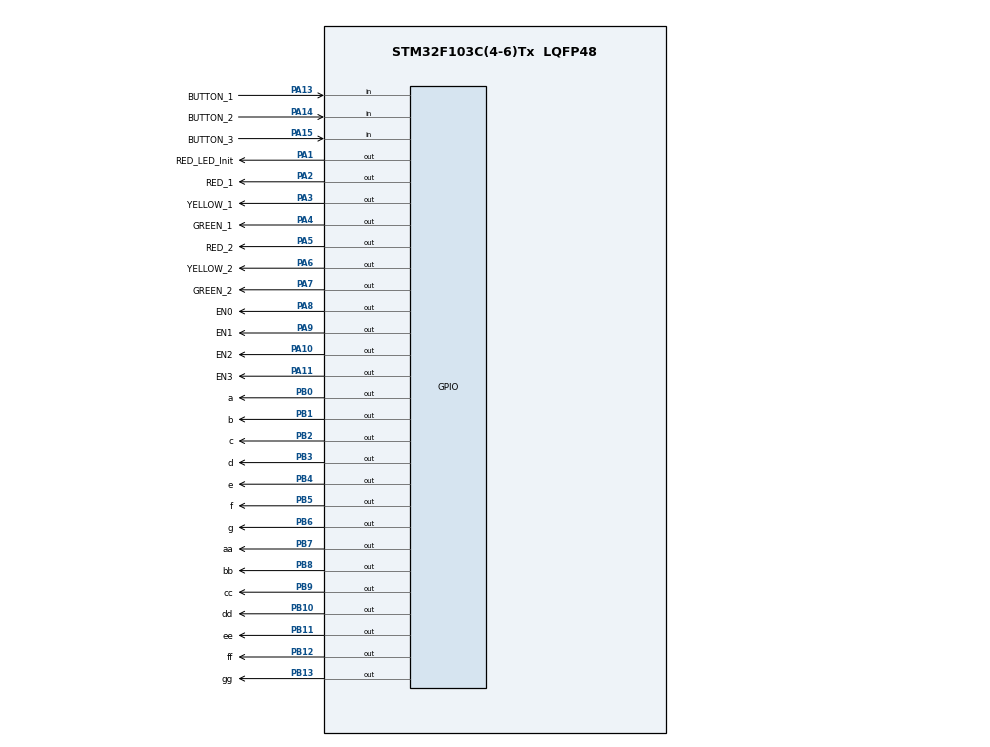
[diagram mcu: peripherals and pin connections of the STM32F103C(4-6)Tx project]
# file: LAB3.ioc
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Mcu.Family=STM32F1
Mcu.Name=STM32F103C(4-6)Tx
Mcu.Package=LQFP48
NVIC.PriorityGroup=NVIC_PRIORITYGROUP_4
NVIC.TIM2_IRQn=true\:1\:0\:true\:false\:true\:true\:true
PA1.GPIO_Label=RED_LED_Init
PA1.GPIO_PuPd=GPIO_PULLUP
PA1.Signal=GPIO_Output
PA10.GPIO_Label=EN2
PA10.Signal=GPIO_Output
PA11.GPIO_Label=EN3
PA11.Signal=GPIO_Output
PA13.GPIO_Label=BUTTON_1
PA13.GPIO_PuPd=GPIO_PULLUP
PA13.Signal=GPIO_Input
PA14.GPIO_Label=BUTTON_2
PA14.GPIO_PuPd=GPIO_PULLUP
PA14.Signal=GPIO_Input
PA15.GPIO_Label=BUTTON_3
PA15.GPIO_PuPd=GPIO_PULLUP
PA15.Signal=GPIO_Input
PA2.GPIO_Label=RED_1
PA2.Signal=GPIO_Output
PA3.GPIO_Label=YELLOW_1
PA3.Signal=GPIO_Output
PA4.GPIO_Label=GREEN_1
PA4.Signal=GPIO_Output
PA5.GPIO_Label=RED_2
PA5.Signal=GPIO_Output
PA6.GPIO_Label=YELLOW_2
PA6.Signal=GPIO_Output
PA7.GPIO_Label=GREEN_2
PA7.Signal=GPIO_Output
PA8.GPIO_Label=EN0
PA8.Signal=GPIO_Output
PA9.GPIO_Label=EN1
PA9.Signal=GPIO_Output
PB0.GPIO_Label=a
PB0.Signal=GPIO_Output
PB1.GPIO_Label=b
PB1.Signal=GPIO_Output
PB10.GPIO_Label=dd
PB10.Signal=GPIO_Output
PB11.GPIO_Label=ee
PB11.Signal=GPIO_Output
PB12.GPIO_Label=ff
PB12.Signal=GPIO_Output
PB13.GPIO_Label=gg
PB13.Signal=GPIO_Output
PB2.GPIO_Label=c
PB2.Signal=GPIO_Output
PB3.GPIO_Label=d
PB3.Signal=GPIO_Output
PB4.GPIO_Label=e
PB4.Signal=GPIO_Output
PB5.GPIO_Label=f
PB5.Signal=GPIO_Output
PB6.GPIO_Label=g
PB6.Signal=GPIO_Output
PB7.GPIO_Label=aa
PB7.Signal=GPIO_Output
PB8.GPIO_Label=bb
PB8.Signal=GPIO_Output
PB9.GPIO_Label=cc
PB9.Signal=GPIO_Output
ProjectManager.HeapSize=0x200
ProjectManager.StackSize=0x400
ProjectManager.TargetToolchain=STM32CubeIDE
RCC.APB1Freq_Value=8000000
RCC.APB2Freq_Value=8000000
TIM2.Period=7999
TIM2.Prescaler=9
VP_SYS_VS_ND.Mode=No_Debug
VP_TIM2_VS_ClockSourceINT.Mode=Internal
board=custom

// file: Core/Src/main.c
/* USER CODE BEGIN Header */
/**
 ******************************************************************************
 * @file           : main.c
 * @brief          : Main program body
 ******************************************************************************
 * @attention
 *
 * <h2><center>&copy; Copyright (c) 2024 STMicroelectronics.
 * All rights reserved.</center></h2>
 *
 * This software component is licensed by ST under BSD 3-Clause license,
 * the "License"; You may not use this file except in compliance with the
 * License. You may obtain a copy of the License at:
 *                        opensource.org/licenses/BSD-3-Clause
 *
 ******************************************************************************
 */
/* USER CODE END Header */
#include "main.h"

/* USER CODE BEGIN Includes */
//#include "fsm_Automatic.h"
#include "software_timer.h"
#include "button.h"
#include "Global.h"
/* USER CODE END Includes */

TIM_HandleTypeDef htim2;

void SystemClock_Config(void);
static void MX_GPIO_Init(void);
static void MX_TIM2_Init(void);

/* USER CODE BEGIN 0 */
//void test_module_MANRED(){
//	if (isButtonPressed(0)) {
//		HAL_GPIO_WritePin(GPIOA, GREEN_1_Pin, LED_ON);
//	}
//	else if (isButtonPressed(2)) {
//		TimeRed = value;
//	}
//	else manual_run(MODE2);
//}
/* USER CODE END 0 */

int main(void)
{

  /* MCU Configuration--------------------------------------------------------*/

  /* Reset of all peripherals, Initializes the Flash interface and the Systick. */
  HAL_Init();

  /* Configure the system clock */
  SystemClock_Config();

  /* Initialize all configured peripherals */
  MX_GPIO_Init();
  MX_TIM2_Init();
  /* USER CODE BEGIN 2 */
	HAL_TIM_Base_Start_IT(&htim2);
//	HAL_GPIO_WritePin(GPIOB,
//			a_Pin |b_Pin | c_Pin | dd_Pin | ee_Pin | ff_Pin | gg_Pin | d_Pin | e_Pin
//					| f_Pin | g_Pin | aa_Pin | bb_Pin | cc_Pin, GPIO_PIN_SET);
//	HAL_GPIO_WritePin(GPIOA,
//			 EN0_Pin | EN1_Pin
//					| EN2_Pin | EN3_Pin, GPIO_PIN_SET);
//	setTimer(5, 1000); //for test module
	//fsm_automatic_init();
//	fsm_manual_init();

	setTimer(1, 239);	//for 4_7SEG
	setTimer(2, 1010);	//for LED_2
//	int TimeForLed1 = 2;
//	setTimer(3, 523); 	//blinking led
//	setTimer(4, 257);	//modified time
	HAL_GPIO_WritePin(GPIOA, ALL_LED, LED_OFF);
	setTimer(0, 1000); 	//for LED_1
  /* USER CODE END 2 */

  /* Infinite loop */
	while (1) {

    /* USER CODE BEGIN 3 */
//		if (HAL_GPIO_ReadPin(GPIOA, BUTTON_1_Pin) == GPIO_PIN_RESET) //pullup: pressed = 0
//			HAL_GPIO_TogglePin(RED_LED_Init_GPIO_Port, RED_LED_Init_Pin);
//		if (isButtonPressed(0) == 1){
//			HAL_GPIO_TogglePin(RED_LED_Init_GPIO_Port, RED_LED_Init_Pin);
//		}
//		if (isButtonPressed(1) == 1){
//			HAL_GPIO_TogglePin(GPIOA, RED_1_Pin);
//		}
//		if (isButtonPressed(2) == 1){
//			HAL_GPIO_TogglePin(GPIOA, RED_2_Pin);
//		}

		fsm_setting_run();
		fsm_automatic_run();
		fsm_manual_run();

//		if (isTimerExpired(5)){
//			HAL_GPIO_TogglePin(GPIOA, RED_1_Pin);
//			setTimer(5, 1000);
//		}
//		test_module_MANRED();

//		if (isTimerExpired(0)) {
////			TimeForLed1--;
////			if (TimeForLed1 <= 0) {
//				HAL_GPIO_TogglePin(GPIOA, RED_1_Pin);
//				setTimer(0, 1000);
////			}
//		}

	}
  /* USER CODE END 3 */
}

void SystemClock_Config(void)
{
  RCC_OscInitTypeDef RCC_OscInitStruct = {0};
  RCC_ClkInitTypeDef RCC_ClkInitStruct = {0};

  /** Initializes the RCC Oscillators according to the specified parameters
  * in the RCC_OscInitTypeDef structure.
  */
  RCC_OscInitStruct.OscillatorType = RCC_OSCILLATORTYPE_HSI;
  RCC_OscInitStruct.HSIState = RCC_HSI_ON;
  RCC_OscInitStruct.HSICalibrationValue = RCC_HSICALIBRATION_DEFAULT;
  RCC_OscInitStruct.PLL.PLLState = RCC_PLL_NONE;
  if (HAL_RCC_OscConfig(&RCC_OscInitStruct) != HAL_OK)
  {
    Error_Handler();
  }
  /** Initializes the CPU, AHB and APB buses clocks
  */
  RCC_ClkInitStruct.ClockType = RCC_CLOCKTYPE_HCLK|RCC_CLOCKTYPE_SYSCLK
                              |RCC_CLOCKTYPE_PCLK1|RCC_CLOCKTYPE_PCLK2;
  RCC_ClkInitStruct.SYSCLKSource = RCC_SYSCLKSOURCE_HSI;
  RCC_ClkInitStruct.AHBCLKDivider = RCC_SYSCLK_DIV1;
  RCC_ClkInitStruct.APB1CLKDivider = RCC_HCLK_DIV1;
  RCC_ClkInitStruct.APB2CLKDivider = RCC_HCLK_DIV1;

  if (HAL_RCC_ClockConfig(&RCC_ClkInitStruct, FLASH_LATENCY_0) != HAL_OK)
  {
    Error_Handler();
  }
}

static void MX_TIM2_Init(void)
{

  TIM_ClockConfigTypeDef sClockSourceConfig = {0};
  TIM_MasterConfigTypeDef sMasterConfig = {0};

  htim2.Instance = TIM2;
  htim2.Init.Prescaler = 9;
  htim2.Init.CounterMode = TIM_COUNTERMODE_UP;
  htim2.Init.Period = 7999;
  htim2.Init.ClockDivision = TIM_CLOCKDIVISION_DIV1;
  htim2.Init.AutoReloadPreload = TIM_AUTORELOAD_PRELOAD_DISABLE;
  if (HAL_TIM_Base_Init(&htim2) != HAL_OK)
  {
    Error_Handler();
  }
  sClockSourceConfig.ClockSource = TIM_CLOCKSOURCE_INTERNAL;
  if (HAL_TIM_ConfigClockSource(&htim2, &sClockSourceConfig) != HAL_OK)
  {
    Error_Handler();
  }
  sMasterConfig.MasterOutputTrigger = TIM_TRGO_RESET;
  sMasterConfig.MasterSlaveMode = TIM_MASTERSLAVEMODE_DISABLE;
  if (HAL_TIMEx_MasterConfigSynchronization(&htim2, &sMasterConfig) != HAL_OK)
  {
    Error_Handler();
  }

}

static void MX_GPIO_Init(void)
{
  GPIO_InitTypeDef GPIO_InitStruct = {0};

  /* GPIO Ports Clock Enable */
  __HAL_RCC_GPIOA_CLK_ENABLE();
  __HAL_RCC_GPIOB_CLK_ENABLE();

  /*Configure GPIO pin Output Level */
  HAL_GPIO_WritePin(GPIOA, RED_LED_Init_Pin|RED_1_Pin|YELLOW_1_Pin|GREEN_1_Pin
                          |RED_2_Pin|YELLOW_2_Pin|GREEN_2_Pin|EN0_Pin
                          |EN1_Pin|EN2_Pin|EN3_Pin, GPIO_PIN_RESET);

  /*Configure GPIO pin Output Level */
  HAL_GPIO_WritePin(GPIOB, a_Pin|b_Pin|c_Pin|dd_Pin
                          |ee_Pin|ff_Pin|gg_Pin|d_Pin
                          |e_Pin|f_Pin|g_Pin|aa_Pin
                          |bb_Pin|cc_Pin, GPIO_PIN_RESET);

  /*Configure GPIO pin : RED_LED_Init_Pin */
  GPIO_InitStruct.Pin = RED_LED_Init_Pin;
  GPIO_InitStruct.Mode = GPIO_MODE_OUTPUT_PP;
  GPIO_InitStruct.Pull = GPIO_PULLUP;
  GPIO_InitStruct.Speed = GPIO_SPEED_FREQ_LOW;
  HAL_GPIO_Init(RED_LED_Init_GPIO_Port, &GPIO_InitStruct);

  /*Configure GPIO pins : RED_1_Pin YELLOW_1_Pin GREEN_1_Pin RED_2_Pin
                           YELLOW_2_Pin GREEN_2_Pin EN0_Pin EN1_Pin
                           EN2_Pin EN3_Pin */
  GPIO_InitStruct.Pin = RED_1_Pin|YELLOW_1_Pin|GREEN_1_Pin|RED_2_Pin
                          |YELLOW_2_Pin|GREEN_2_Pin|EN0_Pin|EN1_Pin
                          |EN2_Pin|EN3_Pin;
  GPIO_InitStruct.Mode = GPIO_MODE_OUTPUT_PP;
  GPIO_InitStruct.Pull = GPIO_NOPULL;
  GPIO_InitStruct.Speed = GPIO_SPEED_FREQ_LOW;
  HAL_GPIO_Init(GPIOA, &GPIO_InitStruct);

  /*Configure GPIO pins : a_Pin b_Pin c_Pin dd_Pin
                           ee_Pin ff_Pin gg_Pin d_Pin
                           e_Pin f_Pin g_Pin aa_Pin
                           bb_Pin cc_Pin */
  GPIO_InitStruct.Pin = a_Pin|b_Pin|c_Pin|dd_Pin
                          |ee_Pin|ff_Pin|gg_Pin|d_Pin
                          |e_Pin|f_Pin|g_Pin|aa_Pin
                          |bb_Pin|cc_Pin;
  GPIO_InitStruct.Mode = GPIO_MODE_OUTPUT_PP;
  GPIO_InitStruct.Pull = GPIO_NOPULL;
  GPIO_InitStruct.Speed = GPIO_SPEED_FREQ_LOW;
  HAL_GPIO_Init(GPIOB, &GPIO_InitStruct);

  /*Configure GPIO pins : BUTTON_1_Pin BUTTON_2_Pin BUTTON_3_Pin */
  GPIO_InitStruct.Pin = BUTTON_1_Pin|BUTTON_2_Pin|BUTTON_3_Pin;
  GPIO_InitStruct.Mode = GPIO_MODE_INPUT;
  GPIO_InitStruct.Pull = GPIO_PULLUP;
  HAL_GPIO_Init(GPIOA, &GPIO_InitStruct);

}

/* USER CODE BEGIN 4 */
void HAL_TIM_PeriodElapsedCallback(TIM_HandleTypeDef *htim) {
	timer_run();
	getInputKey();
}
/* USER CODE END 4 */

void Error_Handler(void)
{
	__disable_irq();
	while (1) {
	}
}

/************************ (C) COPYRIGHT STMicroelectronics *****END OF FILE****/
